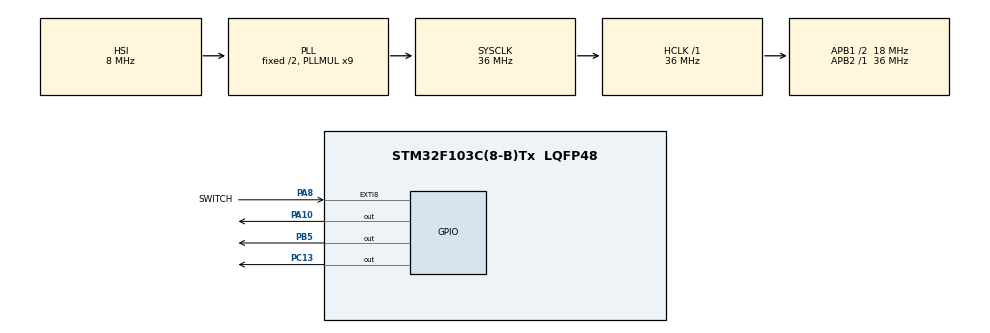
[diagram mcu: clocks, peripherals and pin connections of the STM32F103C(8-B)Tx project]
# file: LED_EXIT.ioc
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Mcu.Family=STM32F1
Mcu.Name=STM32F103C(8-B)Tx
Mcu.Package=LQFP48
NVIC.EXTI9_5_IRQn=true\:0\:0\:false\:false\:true\:true\:true\:true
NVIC.PriorityGroup=NVIC_PRIORITYGROUP_4
PA10.Signal=GPIO_Output
PA13.Mode=Serial_Wire
PA13.Signal=SYS_JTMS-SWDIO
PA14.Mode=Serial_Wire
PA14.Signal=SYS_JTCK-SWCLK
PA8.GPIO_Label=SWITCH
PA8.GPIO_ModeDefaultEXTI=GPIO_MODE_IT_RISING_FALLING
PA8.Signal=GPXTI8
PB5.Signal=GPIO_Output
PC13-TAMPER-RTC.Signal=GPIO_Output
ProjectManager.HeapSize=0x200
ProjectManager.StackSize=0x400
ProjectManager.TargetToolchain=MDK-ARM V5.32
RCC.AHBFreq_Value=36000000
RCC.APB1CLKDivider=RCC_HCLK_DIV2
RCC.APB1Freq_Value=18000000
RCC.APB1TimFreq_Value=36000000
RCC.APB2Freq_Value=36000000
RCC.APB2TimFreq_Value=36000000
RCC.HCLKFreq_Value=36000000
RCC.PLLMUL=RCC_PLL_MUL9
RCC.SYSCLKFreq_VALUE=36000000
RCC.SYSCLKSource=RCC_SYSCLKSOURCE_PLLCLK
RCC.USBFreq_Value=36000000
board=custom

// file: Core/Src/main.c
/* USER CODE BEGIN Header */
/**
  ******************************************************************************
  * @file           : main.c
  * @brief          : Main program body
  ******************************************************************************
  * @attention
  *
  * Copyright (c) 2023 STMicroelectronics.
  * All rights reserved.
  *
  * This software is licensed under terms that can be found in the LICENSE file
  * in the root directory of this software component.
  * If no LICENSE file comes with this software, it is provided AS-IS.
  *
  ******************************************************************************
  */
/* USER CODE END Header */
#include "main.h"
#include "gpio.h"

void SystemClock_Config(void);
/* USER CODE BEGIN PFP */
int flag=0;
int HIGH_NUM=0;
int LIGHT_NUM=0;
/* USER CODE END PFP */

/* USER CODE BEGIN 0 */
void HAL_GPIO_EXTI_Callback(uint16_t GPIO_Pin){
	HIGH_NUM+=1;
	if (flag==0){
	flag=1;
	}
}
/* USER CODE END 0 */

int main(void)
{

  /* MCU Configuration--------------------------------------------------------*/

  /* Reset of all peripherals, Initializes the Flash interface and the Systick. */
  HAL_Init();

  /* Configure the system clock */
  SystemClock_Config();

  /* Initialize all configured peripherals */
  MX_GPIO_Init();

  /* Infinite loop */
  /* USER CODE BEGIN WHILE */
  while (1)
  {
		if (flag==1){
			int TEST_NUM=HIGH_NUM;
			HAL_Delay(20);
			if (TEST_NUM==HIGH_NUM){
			flag=0;
			HIGH_NUM=0;
			LIGHT_NUM=0;
			}
		}
    /* USER CODE END WHILE */
    if (flag==1){
		if (LIGHT_NUM%3==0){
			      		//红灯亮
		HAL_GPIO_WritePin(GPIOA, GPIO_PIN_10, GPIO_PIN_SET);
		HAL_GPIO_WritePin(GPIOB, GPIO_PIN_5, GPIO_PIN_RESET);
		HAL_GPIO_WritePin(GPIOC, GPIO_PIN_13, GPIO_PIN_SET);
		}

		else if (LIGHT_NUM%3==1){
					HAL_GPIO_WritePin(GPIOA, GPIO_PIN_10, GPIO_PIN_RESET);
		HAL_GPIO_WritePin(GPIOB, GPIO_PIN_5, GPIO_PIN_SET);
		HAL_GPIO_WritePin(GPIOC, GPIO_PIN_13, GPIO_PIN_SET);
		}
		else if (LIGHT_NUM%3==2){
					HAL_GPIO_WritePin(GPIOA, GPIO_PIN_10, GPIO_PIN_RESET);
		HAL_GPIO_WritePin(GPIOB, GPIO_PIN_5, GPIO_PIN_RESET);
		HAL_GPIO_WritePin(GPIOC, GPIO_PIN_13, GPIO_PIN_RESET);
		}
		LIGHT_NUM+=1;
		HAL_Delay(1000);
    }
		else {
		HAL_GPIO_WritePin(GPIOA, GPIO_PIN_10, GPIO_PIN_RESET);
		HAL_GPIO_WritePin(GPIOB, GPIO_PIN_5, GPIO_PIN_RESET);
		HAL_GPIO_WritePin(GPIOC, GPIO_PIN_13, GPIO_PIN_SET);
		}
  }
}

void SystemClock_Config(void)
{
  RCC_OscInitTypeDef RCC_OscInitStruct = {0};
  RCC_ClkInitTypeDef RCC_ClkInitStruct = {0};

  /** Initializes the RCC Oscillators according to the specified parameters
  * in the RCC_OscInitTypeDef structure.
  */
  RCC_OscInitStruct.OscillatorType = RCC_OSCILLATORTYPE_HSI;
  RCC_OscInitStruct.HSIState = RCC_HSI_ON;
  RCC_OscInitStruct.HSICalibrationValue = RCC_HSICALIBRATION_DEFAULT;
  RCC_OscInitStruct.PLL.PLLState = RCC_PLL_ON;
  RCC_OscInitStruct.PLL.PLLSource = RCC_PLLSOURCE_HSI_DIV2;
  RCC_OscInitStruct.PLL.PLLMUL = RCC_PLL_MUL9;
  if (HAL_RCC_OscConfig(&RCC_OscInitStruct) != HAL_OK)
  {
    Error_Handler();
  }

  /** Initializes the CPU, AHB and APB buses clocks
  */
  RCC_ClkInitStruct.ClockType = RCC_CLOCKTYPE_HCLK|RCC_CLOCKTYPE_SYSCLK
                              |RCC_CLOCKTYPE_PCLK1|RCC_CLOCKTYPE_PCLK2;
  RCC_ClkInitStruct.SYSCLKSource = RCC_SYSCLKSOURCE_PLLCLK;
  RCC_ClkInitStruct.AHBCLKDivider = RCC_SYSCLK_DIV1;
  RCC_ClkInitStruct.APB1CLKDivider = RCC_HCLK_DIV2;
  RCC_ClkInitStruct.APB2CLKDivider = RCC_HCLK_DIV1;

  if (HAL_RCC_ClockConfig(&RCC_ClkInitStruct, FLASH_LATENCY_1) != HAL_OK)
  {
    Error_Handler();
  }
}

void Error_Handler(void)
{
  __disable_irq();
  while (1)
  {
  }
}
